VERSION ""

NS_ :

BS_:

BU_: XXX

BO_ 85 CID_SZBTJF: 8 XXX
 SG_ sig_luqbvx : 40|1@1+ (1,0) [0|1] "" XXX
 SG_ sig_nhjxpa : 56|8@1+ (1,0) [0|255] "" XXX

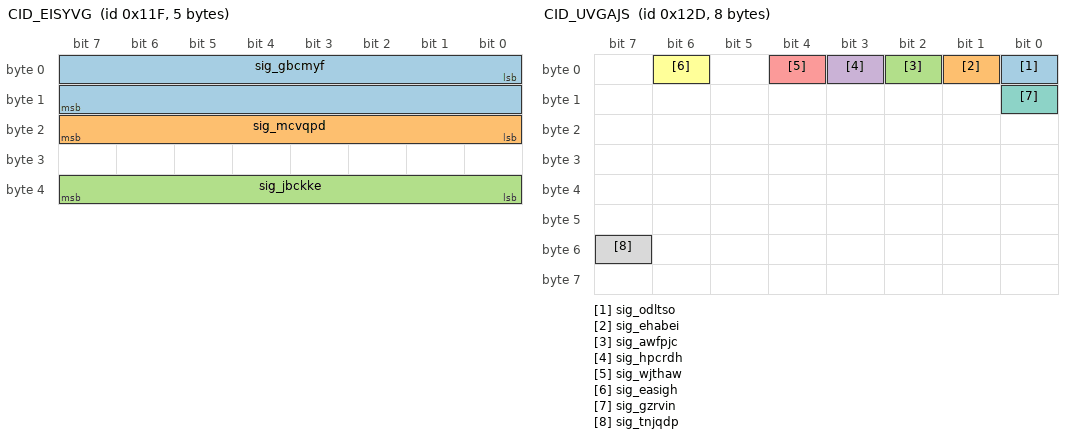
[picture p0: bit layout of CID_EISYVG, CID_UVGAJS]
BO_ 287 CID_EISYVG: 5 XXX
 SG_ sig_gbcmyf : 0|16@1- (0.1,0) [-450|450] "" XXX
 SG_ sig_mcvqpd : 16|8@1+ (4,0) [0|1020] "" XXX
 SG_ sig_jbckke : 32|8@1+ (1,0) [0|255] "" XXX

BO_ 289 CID_FFFEGC: 8 XXX
 SG_ sig_lrsfif : 0|12@1+ (1,0) [0|255] "" XXX

BO_ 301 CID_UVGAJS: 8 XXX
 SG_ sig_odltso : 0|1@0+ (1,0) [0|1] "" XXX
 SG_ sig_ehabei : 1|1@0+ (1,0) [0|1] "" XXX
 SG_ sig_awfpjc : 2|1@0+ (1,0) [0|1] "" XXX
 SG_ sig_hpcrdh : 3|1@0+ (1,0) [0|1] "" XXX
 SG_ sig_wjthaw : 4|1@0+ (1,0) [0|1] "" XXX
 SG_ sig_easigh : 6|1@0+ (1,0) [0|1] "" XXX
 SG_ sig_gzrvin : 8|1@0+ (1,0) [0|1] "" XXX
 SG_ sig_tnjqdp : 55|1@0+ (1,0) [0|1] "" XXX

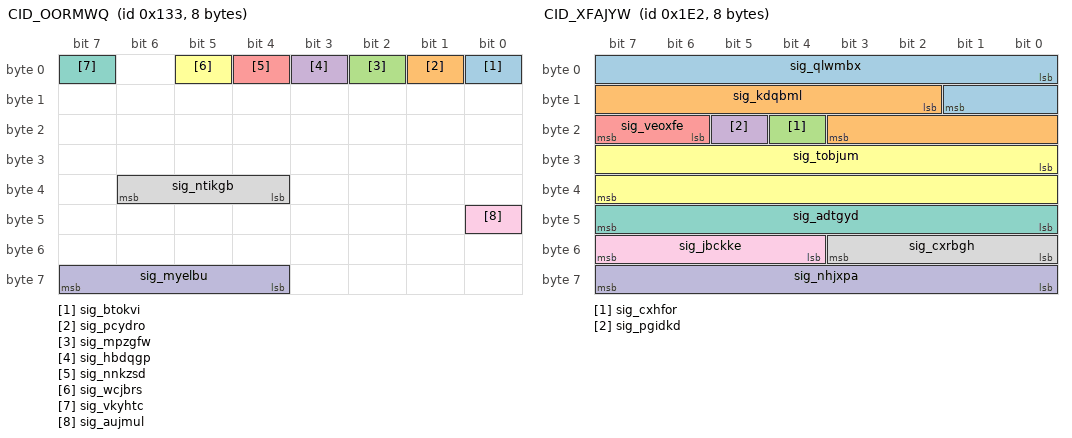
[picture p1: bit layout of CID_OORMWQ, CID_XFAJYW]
BO_ 307 CID_OORMWQ: 8 XXX
 SG_ sig_btokvi : 0|1@0+ (1,0) [0|1] "" XXX
 SG_ sig_pcydro : 1|1@1+ (1,0) [0|1] "" XXX
 SG_ sig_mpzgfw : 2|1@1+ (1,0) [0|1] "" XXX
 SG_ sig_hbdqgp : 3|1@1+ (1,0) [0|1] "" XXX
 SG_ sig_nnkzsd : 4|1@0+ (1,0) [0|1] "" XXX
 SG_ sig_wcjbrs : 5|1@0+ (1,0) [0|1] "" XXX
 SG_ sig_vkyhtc : 7|1@0+ (1,0) [0|1] "" XXX
 SG_ sig_ntikgb : 36|3@1+ (1,0) [0|7] "" XXX
 SG_ sig_aujmul : 40|1@0+ (1,0) [0|1] "" XXX
 SG_ sig_myelbu : 63|4@0+ (1,0) [0|15] "" XXX

BO_ 482 CID_XFAJYW: 8 XXX
 SG_ sig_qlwmbx : 0|10@1- (0.01,0) [0|5] "" XXX
 SG_ sig_kdqbml : 10|10@1- (0.01,0) [-5|0] "" XXX
 SG_ sig_cxhfor : 20|1@0+ (1,0) [0|1] "" XXX
 SG_ sig_pgidkd : 21|1@0+ (1,0) [0|1] "" XXX
 SG_ sig_veoxfe : 22|2@1+ (1,0) [0|1] "" XXX
 SG_ sig_tobjum : 24|16@1- (0.1,0) [-780|779.9] "" XXX
 SG_ sig_adtgyd : 47|8@0+ (1,0) [0|255] "" XXX
 SG_ sig_cxrbgh : 48|4@1+ (1,0) [0|15] "" XXX
 SG_ sig_jbckke : 52|4@1+ (1,0) [0|15] "" XXX
 SG_ sig_nhjxpa : 56|8@1+ (1,0) [0|255] "" XXX

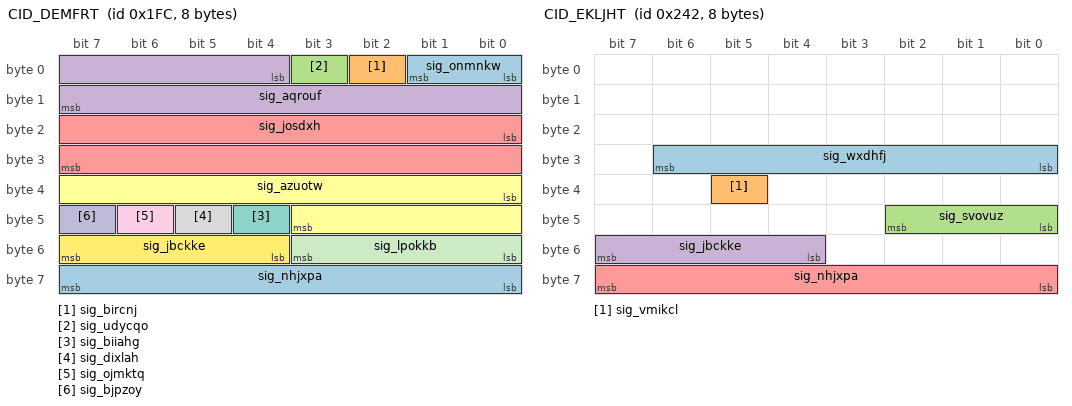
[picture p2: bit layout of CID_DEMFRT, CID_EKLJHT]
BO_ 508 CID_DEMFRT: 8 XXX
 SG_ sig_onmnkw : 0|2@1+ (1,0) [0|1] "" XXX
 SG_ sig_bircnj : 2|1@1+ (1,0) [0|1] "" XXX
 SG_ sig_udycqo : 3|1@0+ (1,0) [0|1] "" XXX
 SG_ sig_aqrouf : 4|12@1- (1,0) [-2048|2047] "" XXX
 SG_ sig_josdxh : 16|16@1- (0.1,0) [-780|779.9] "Deg" XXX
 SG_ sig_azuotw : 32|12@1- (1,0) [0|63] "" XXX
 SG_ sig_biiahg : 44|1@0+ (1,0) [0|1] "" XXX
 SG_ sig_dixlah : 45|1@1+ (1,0) [0|255] "" XXX
 SG_ sig_ojmktq : 46|1@1+ (1,0) [0|1] "" XXX
 SG_ sig_bjpzoy : 47|1@0+ (1,0) [0|3] "" XXX
 SG_ sig_lpokkb : 48|4@1+ (1,0) [0|15] "" XXX
 SG_ sig_jbckke : 52|4@1+ (1,0) [0|15] "" XXX
 SG_ sig_nhjxpa : 56|8@1+ (1,0) [0|255] "" XXX

BO_ 578 CID_EKLJHT: 8 XXX
 SG_ sig_wxdhfj : 30|7@0+ (1,0) [0|127] "" XXX
 SG_ sig_vmikcl : 37|1@0+ (1,0) [0|1] "" XXX
 SG_ sig_svovuz : 40|3@1+ (1,0) [0|7] "" XXX
 SG_ sig_jbckke : 55|4@0+ (1,0) [0|15] "" XXX
 SG_ sig_nhjxpa : 56|8@1+ (1,0) [0|255] "" XXX

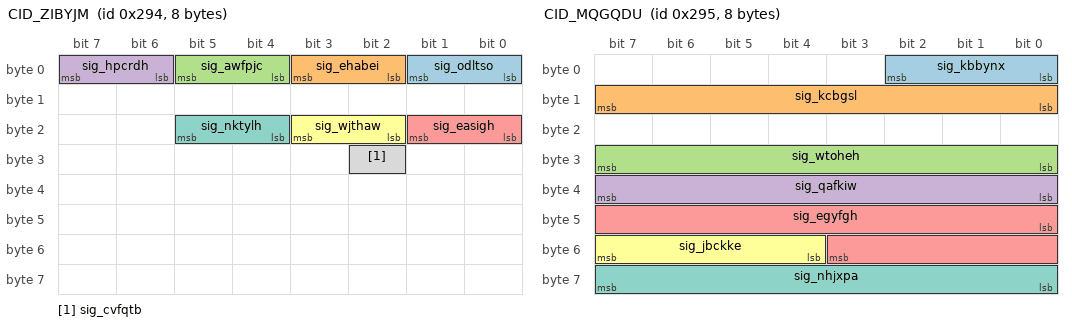
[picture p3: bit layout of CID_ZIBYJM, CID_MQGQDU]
BO_ 660 CID_ZIBYJM: 8 XXX
 SG_ sig_odltso : 1|2@0+ (1,0) [0|3] "" XXX
 SG_ sig_ehabei : 3|2@0+ (1,0) [0|3] "" XXX
 SG_ sig_awfpjc : 5|2@0+ (1,0) [0|3] "" XXX
 SG_ sig_hpcrdh : 7|2@0+ (1,0) [0|3] "" XXX
 SG_ sig_easigh : 17|2@0+ (1,0) [0|3] "" XXX
 SG_ sig_wjthaw : 19|2@0+ (1,0) [0|3] "" XXX
 SG_ sig_nktylh : 21|2@0+ (1,0) [0|3] "" XXX
 SG_ sig_cvfqtb : 26|1@0+ (1,0) [0|1] "" XXX

BO_ 661 CID_MQGQDU: 8 XXX
 SG_ sig_kbbynx : 2|3@0+ (1,0) [0|7] "" XXX
 SG_ sig_kcbgsl : 15|8@0+ (1,0) [0|255] "" XXX
 SG_ sig_wtoheh : 31|8@0+ (1,0) [0|255] "" XXX
 SG_ sig_qafkiw : 32|8@1+ (1,0) [0|255] "" XXX
 SG_ sig_egyfgh : 40|12@1+ (1,0) [0|255] "" XXX
 SG_ sig_jbckke : 52|4@1+ (1,0) [0|15] "" XXX
 SG_ sig_nhjxpa : 63|8@0+ (1,0) [0|255] "" XXX

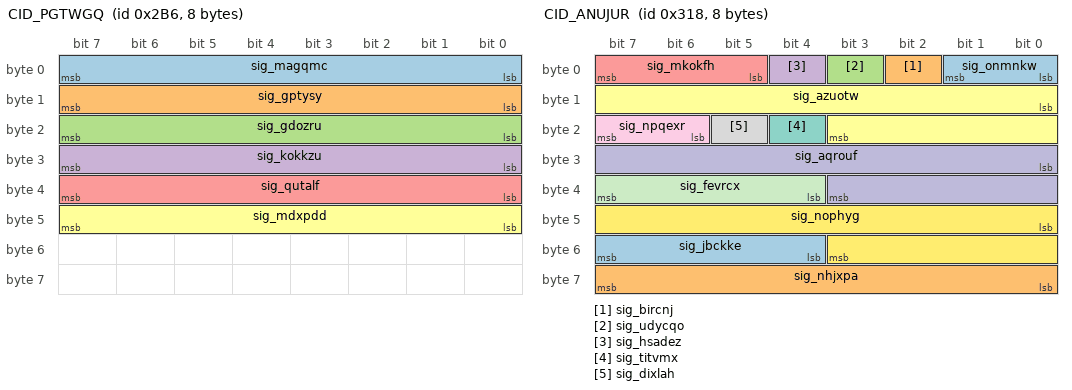
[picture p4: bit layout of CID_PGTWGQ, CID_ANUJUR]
BO_ 694 CID_PGTWGQ: 8 XXX
 SG_ sig_magqmc : 7|8@0+ (1,0) [0|255] "" XXX
 SG_ sig_gptysy : 15|8@0+ (1,0) [0|255] "" XXX
 SG_ sig_gdozru : 23|8@0+ (1,0) [0|255] "" XXX
 SG_ sig_kokkzu : 31|8@0+ (1,0) [0|255] "" XXX
 SG_ sig_qutalf : 39|8@0+ (1,0) [0|255] "" XXX
 SG_ sig_mdxpdd : 47|8@0+ (1,0) [0|255] "" XXX

BO_ 790 CID_LZMJZB: 8 XXX
 SG_ sig_ednhmw : 3|4@0+ (1,0) [0|1] "" XXX
 SG_ sig_lbzbva : 4|2@1+ (1,0) [0|3] "" XXX
 SG_ sig_qcsskh : 6|2@1+ (1,0) [0|3] "" XXX
 SG_ sig_bcgqhy : 8|2@1+ (1,0) [0|3] "" XXX
 SG_ sig_tkymle : 10|1@1+ (1,0) [0|1] "" XXX
 SG_ sig_dkcweq : 11|4@1+ (1,0) [0|1] "" XXX
 SG_ sig_huvkmm : 15|1@0+ (1,0) [0|1] "" XXX
 SG_ sig_tobjum : 16|11@1- (1,0) [-1024|1023] "" XXX
 SG_ sig_cxhfor : 27|1@1+ (1,0) [0|1] "" XXX
 SG_ sig_pgidkd : 28|1@1+ (1,0) [0|3] "" XXX
 SG_ sig_okdxqc : 29|1@0+ (1,0) [0|1] "" XXX
 SG_ sig_pirhcz : 30|1@0+ (1,0) [0|1] "" XXX
 SG_ sig_nofkfe : 31|1@0+ (1,0) [0|1] "" XXX
 SG_ sig_xyuuab : 32|2@1+ (1,0) [0|3] "" XXX
 SG_ sig_folhtx : 34|2@1+ (1,0) [0|3] "" XXX
 SG_ sig_dunuaq : 36|4@1+ (1,0) [0|3] "" XXX
 SG_ sig_kwqhlp : 40|8@1+ (5,-5) [-5|1270] "" XXX
 SG_ sig_xdhcut : 49|2@0+ (1,0) [0|3] "" XXX
 SG_ sig_wulwxz : 51|2@0+ (1,0) [0|3] "" XXX
 SG_ sig_jbckke : 52|4@1+ (1,0) [0|15] "" XXX
 SG_ sig_nhjxpa : 56|8@1+ (1,0) [0|15] "" XXX

BO_ 792 CID_ANUJUR: 8 XXX
 SG_ sig_onmnkw : 0|2@1+ (1,0) [0|1] "" XXX
 SG_ sig_bircnj : 2|1@1+ (1,0) [0|1] "" XXX
 SG_ sig_udycqo : 3|1@1+ (1,0) [0|1] "" XXX
 SG_ sig_hsadez : 4|1@1+ (1,0) [0|1] "" XXX
 SG_ sig_mkokfh : 5|3@1+ (1,0) [0|1] "" XXX
 SG_ sig_azuotw : 8|12@1- (1,0) [-2048|2047] "" XXX
 SG_ sig_titvmx : 20|1@1+ (1,0) [0|1] "" XXX
 SG_ sig_dixlah : 21|1@1+ (1,0) [0|1] "" XXX
 SG_ sig_npqexr : 22|2@1+ (1,0) [0|15] "" XXX
 SG_ sig_aqrouf : 24|12@1- (1,0) [-2048|2047] "" XXX
 SG_ sig_fevrcx : 36|4@1+ (1,0) [0|15] "" XXX
 SG_ sig_nophyg : 40|12@1+ (1,0) [0|4095] "" XXX
 SG_ sig_jbckke : 52|4@1+ (1,0) [0|15] "" XXX
 SG_ sig_nhjxpa : 56|8@1+ (1,0) [0|255] "" XXX

BO_ 813 CID_PTRYDZ: 8 XXX
 SG_ sig_blrlpk : 0|9@1+ (0.5,0) [0|255.5] "" XXX
 SG_ sig_wfmcgt : 9|1@1+ (1,0) [0|1] "" XXX
 SG_ sig_djewoy : 10|3@1+ (1,0) [0|7] "" XXX
 SG_ sig_tyqdrb : 13|3@1+ (1,0) [0|7] "" XXX
 SG_ sig_psstme : 16|1@1+ (1,0) [0|1] "" XXX
 SG_ sig_egpevu : 17|1@1+ (1,0) [0|1] "" XXX
 SG_ sig_udycqo : 18|1@1+ (1,0) [0|1] "" XXX
 SG_ sig_ovjhjx : 19|3@1+ (1,0) [0|1] "" XXX
 SG_ sig_hdrvua : 22|1@0+ (1,0) [0|1] "" XXX
 SG_ sig_xosdqk : 23|1@0+ (1,0) [0|1] "" XXX
 SG_ sig_bcgqhy : 24|1@1+ (1,0) [0|1] "" XXX
 SG_ sig_bvgrpl : 25|7@1+ (1,0) [0|127] "" XXX
 SG_ sig_rhmxqr : 32|4@1+ (1,0) [0|15] "" XXX
 SG_ sig_lsximb : 36|12@1+ (1,0) [0|4095] "" XXX
 SG_ sig_jbckke : 48|4@1+ (1,0) [0|15] "" XXX
 SG_ sig_wlalxs : 55|4@0+ (1,0) [0|15] "" XXX
 SG_ sig_nhjxpa : 56|8@1+ (1,0) [0|255] "" XXX

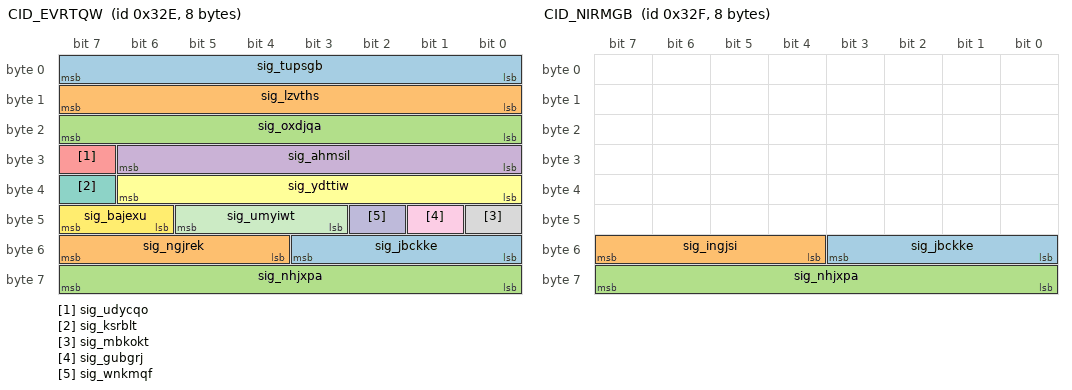
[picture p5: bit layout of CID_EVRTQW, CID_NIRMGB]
BO_ 814 CID_EVRTQW: 8 XXX
 SG_ sig_tupsgb : 0|8@1+ (0.05,-5) [-100|155] "" XXX
 SG_ sig_lzvths : 8|8@1+ (0.05,-5) [0|1.26] "" XXX
 SG_ sig_oxdjqa : 16|8@1+ (0.05,-5) [0|1.26] "" XXX
 SG_ sig_ahmsil : 24|7@1+ (0.2,0) [0|12.7] "" XXX
 SG_ sig_udycqo : 31|1@0+ (1,0) [0|1] "" XXX
 SG_ sig_ydttiw : 32|7@1+ (0.2,-16) [0|12.7] "" XXX
 SG_ sig_ksrblt : 39|1@0+ (1,0) [0|1] "" XXX
 SG_ sig_mbkokt : 40|1@0+ (1,0) [0|1] "" XXX
 SG_ sig_gubgrj : 41|1@0+ (1,0) [0|1] "" XXX
 SG_ sig_wnkmqf : 42|1@1+ (1,0) [0|3] "" XXX
 SG_ sig_umyiwt : 45|3@0+ (1,0) [0|1] "" XXX
 SG_ sig_bajexu : 46|2@1+ (1,0) [0|3] "" XXX
 SG_ sig_jbckke : 48|4@1+ (1,0) [0|15] "" XXX
 SG_ sig_ngjrek : 55|4@0+ (1,0) [0|15] "" XXX
 SG_ sig_nhjxpa : 56|8@1+ (1,0) [0|255] "" XXX

BO_ 815 CID_NIRMGB: 8 XXX
 SG_ sig_jbckke : 48|4@1+ (1,0) [0|15] "" XXX
 SG_ sig_ingjsi : 55|4@0+ (1,0) [0|15] "" XXX
 SG_ sig_nhjxpa : 56|8@1+ (1,0) [0|255] "" XXX

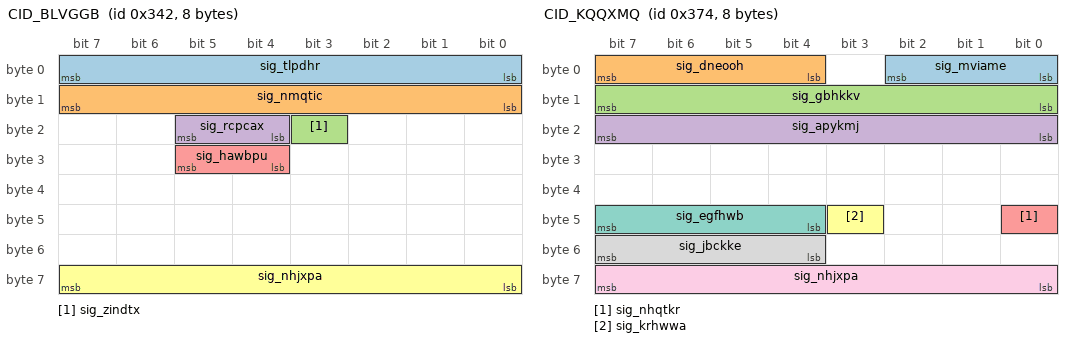
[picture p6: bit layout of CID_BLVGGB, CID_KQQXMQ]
BO_ 834 CID_BLVGGB: 8 XXX
 SG_ sig_tlpdhr : 0|8@1+ (0.01,0) [0|2.55] "" XXX
 SG_ sig_nmqtic : 8|8@1+ (0.01,0) [0|2.55] "" XXX
 SG_ sig_zindtx : 19|1@1+ (1,0) [0|1] "" XXX
 SG_ sig_rcpcax : 20|2@1+ (1,0) [0|255] "" XXX
 SG_ sig_hawbpu : 28|2@1+ (1,0) [0|1] "" XXX
 SG_ sig_nhjxpa : 56|8@1+ (1,0) [0|255] "" XXX

BO_ 884 CID_KQQXMQ: 8 MRR
 SG_ sig_mviame : 2|3@0+ (1,0) [0|3] "" MRR
 SG_ sig_dneooh : 7|4@0+ (1,0) [0|15] "" MRR
 SG_ sig_gbhkkv : 15|8@0+ (0.1,-12) [0|255] "" MRR
 SG_ sig_apykmj : 23|8@0+ (1,-100) [0|255] "" MRR
 SG_ sig_nhqtkr : 40|1@0+ (1,0) [0|3] "" MRR
 SG_ sig_krhwwa : 43|1@0+ (1,0) [0|1] "" XXX
 SG_ sig_egfhwb : 44|4@1+ (1,0) [0|15] "" XXX
 SG_ sig_jbckke : 52|4@1+ (1,0) [0|15] "" MRR
 SG_ sig_nhjxpa : 56|8@1+ (1,0) [0|255] "" MRR

BO_ 944 CID_NQVCNT: 8 XXX
 SG_ sig_elzknc : 1|2@0+ (1,0) [0|3] "" XXX
 SG_ sig_khkynu : 2|1@0+ (1,0) [0|1] "" XXX
 SG_ sig_txheja : 4|2@0+ (1,0) [0|3] "" XXX
 SG_ sig_mobrfy : 5|1@0+ (1,0) [0|1] "" XXX
 SG_ sig_wvkrpo : 6|1@0+ (1,0) [0|1] "" XXX
 SG_ sig_ogphgi : 7|1@0+ (1,0) [0|1] "" XXX
 SG_ sig_zytbxi : 8|1@0+ (1,0) [0|1] "" XXX
 SG_ sig_qgdfqe : 11|3@0+ (1,0) [0|7] "" XXX
 SG_ sig_cgntlm : 12|1@0+ (1,0) [0|1] "" XXX
 SG_ sig_zeuzcd : 14|2@0+ (1,0) [0|3] "" XXX
 SG_ sig_fnshzh : 15|1@0+ (1,0) [0|1] "" XXX
 SG_ sig_ahezcb : 16|1@0+ (1,0) [0|1] "" XXX
 SG_ sig_kkpwmp : 18|2@0+ (1,0) [0|3] "" XXX
 SG_ sig_cqfqgy : 19|1@0+ (1,0) [0|1] "" XXX
 SG_ sig_mfalah : 23|4@0+ (1,0) [0|15] "" XXX
 SG_ sig_turftj : 24|28@1+ (1,0) [0|268435455] "" XXX
 SG_ sig_jbckke : 52|4@1+ (1,0) [0|15] "" XXX
 SG_ sig_nhjxpa : 56|8@1+ (1,0) [0|255] "" XXX

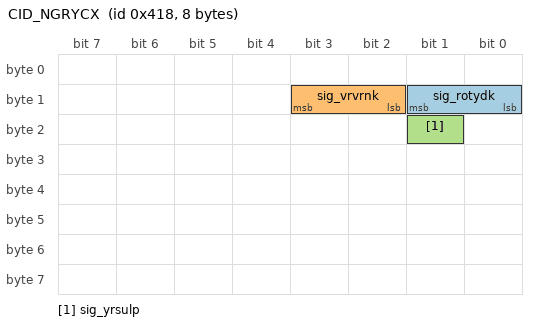
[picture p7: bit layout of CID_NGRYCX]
BO_ 1048 CID_NGRYCX: 8 XXX
 SG_ sig_rotydk : 9|2@0+ (1,0) [0|1] "" XXX
 SG_ sig_vrvrnk : 11|2@0+ (1,0) [0|1] "" XXX
 SG_ sig_yrsulp : 17|1@0+ (1,0) [0|1] "" XXX

VAL_ 578 sig_svovuz 4 "D" 2 "R" 3 "N" 1 "P";
VAL_ 790 sig_ednhmw 11 "AutoFullBeamActive" 2 "AutoFullBeamInactive";
VAL_ 790 sig_lbzbva 0 "GRAY" 1 "GREEN" 2 "YELLOW" 3 "RED";
VAL_ 790 sig_qcsskh 3 "ALARM_AND_LKA" 2 "LKA" 1 "ALARM" 0 "DISABLE";
VAL_ 790 sig_folhtx 0 "GRAY" 1 "GREEN" 2 "YELLOW" 3 "RED";
VAL_ 790 sig_xdhcut 0 "VIBRATION" 1 "AUDIO" 2 "AUDIO_AND_VIBRATION";
VAL_ 792 sig_onmnkw 0 "NotReady" 1 "Ready" 2 "Active" 3 "TemporaryFail";
VAL_ 813 sig_djewoy 4 "4BAR" 3 "3BAR" 2 "2BAR" 1 "1BAR";
VAL_ 813 sig_ovjhjx 0 "OFF" 2 "ACC_ON" 3 "ACC_ACTIVE" 5 "FORCE_ACCEL" 7 "ERROR";
VAL_ 813 sig_bvgrpl 36 "ACC_ERROR" 22 "OVERRIDE" 12 "ENGAGE" 8 "DISENGAGE" 20 "ACC_ON" 32 "ACC_OFF" 48 "CHECK_GEAR_D" 16 "FORCE_ACCEL" 0 "NONE";
VAL_ 814 sig_umyiwt 0 "Off" 1 "Passive" 2 "StandBy" 3 "ActiveControl" 4 "BrakeOnly" 5 "Override" 6 "Standstill" 7 "Failure";
VAL_ 814 sig_bajexu 0 "Softoff" 1 "Fastoff" 2 "Immediateoff" 3 "Initial";
VAL_ 834 sig_rcpcax 2 "SPORT" 1 "ECO" 0 "SNOW";
VAL_ 834 sig_hawbpu 3 "HEV" 2 "FORCE_EV" 1 "EV";
VAL_ 944 sig_txheja 0 "NOTPRESSED" 1 "DOWN_SETSPEED" 3 "UP_RESETSPEED";
